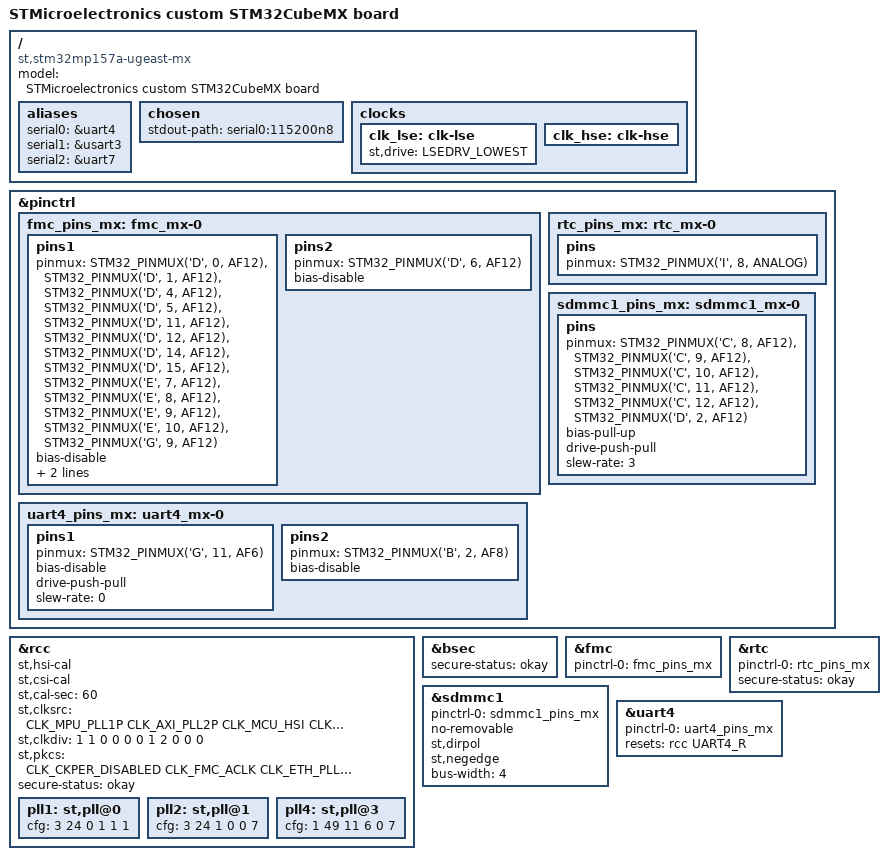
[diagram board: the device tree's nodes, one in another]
/* SPDX-License-Identifier: (GPL-2.0+ OR BSD-3-Clause) */
/*
 * Copyright (C) STMicroelectronics 2019 - All Rights Reserved
 * Author: STM32CubeMX code generation for STMicroelectronics.
 */

/dts-v1/;
#include <dt-bindings/clock/stm32mp1-clksrc.h>
#include "stm32mp15-mx.h"

#include "stm32mp157c.dtsi"
#include "stm32mp157cac-pinctrl.dtsi"
#include "stm32mp15-ddr.dtsi"
#include "stm32mp157c-security.dtsi"

/* USER CODE BEGIN includes */
/* USER CODE END includes */

/ {
	model = "STMicroelectronics custom STM32CubeMX board";
	compatible = "st,stm32mp157a-ugeast-mx", "st,stm32mp157";

	/* USER CODE BEGIN root */

	aliases {
		serial0 = &uart4;
		serial1 = &usart3;
		serial2 = &uart7;
	};

	chosen {
		stdout-path = "serial0:115200n8";
	};

	/* USER CODE END root */

clocks {
    /* USER CODE BEGIN clocks */
    /* USER CODE END clocks */

    clk_lse: clk-lse {
        /* USER CODE BEGIN clocks */
        /* USER CODE END clocks */
        st,drive=<LSEDRV_LOWEST>;
    };
    clk_hse: clk-hse {
        /* USER CODE BEGIN clocks */
        /* USER CODE END clocks */
    };
};

}; /*root*/

&pinctrl {
    fmc_pins_mx: fmc_mx-0 {
        pins1 {
            pinmux = <STM32_PINMUX('D', 0, AF12)>, /* FMC_D2 */
                     <STM32_PINMUX('D', 1, AF12)>, /* FMC_D3 */
                     <STM32_PINMUX('D', 4, AF12)>, /* FMC_NOE */
                     <STM32_PINMUX('D', 5, AF12)>, /* FMC_NWE */
                     <STM32_PINMUX('D', 11, AF12)>, /* FMC_CLE */
                     <STM32_PINMUX('D', 12, AF12)>, /* FMC_ALE */
                     <STM32_PINMUX('D', 14, AF12)>, /* FMC_D0 */
                     <STM32_PINMUX('D', 15, AF12)>, /* FMC_D1 */
                     <STM32_PINMUX('E', 7, AF12)>, /* FMC_D4 */
                     <STM32_PINMUX('E', 8, AF12)>, /* FMC_D5 */
                     <STM32_PINMUX('E', 9, AF12)>, /* FMC_D6 */
                     <STM32_PINMUX('E', 10, AF12)>, /* FMC_D7 */
                     <STM32_PINMUX('G', 9, AF12)>; /* FMC_NCE */
            bias-disable;
            drive-push-pull;
            slew-rate = <1>;
        };
        pins2 {
            pinmux = <STM32_PINMUX('D', 6, AF12)>; /* FMC_NWAIT */
            bias-disable;
        };
    };
    rtc_pins_mx: rtc_mx-0 {
        pins {
            pinmux = <STM32_PINMUX('I', 8, ANALOG)>; /* RTC_LSCO */
        };
    };
    sdmmc1_pins_mx: sdmmc1_mx-0 {
        pins {
            pinmux = <STM32_PINMUX('C', 8, AF12)>, /* SDMMC1_D0 */
                     <STM32_PINMUX('C', 9, AF12)>, /* SDMMC1_D1 */
                     <STM32_PINMUX('C', 10, AF12)>, /* SDMMC1_D2 */
                     <STM32_PINMUX('C', 11, AF12)>, /* SDMMC1_D3 */
                     <STM32_PINMUX('C', 12, AF12)>, /* SDMMC1_CK */
                     <STM32_PINMUX('D', 2, AF12)>; /* SDMMC1_CMD */
            bias-pull-up;
            drive-push-pull;
            slew-rate = <3>;
        };
    };
    uart4_pins_mx: uart4_mx-0 {
        pins1 {
            pinmux = <STM32_PINMUX('G', 11, AF6)>; /* UART4_TX */
            bias-disable;
            drive-push-pull;
            slew-rate = <0>;
        };
        pins2 {
            pinmux = <STM32_PINMUX('B', 2, AF8)>; /* UART4_RX */
            bias-disable;
        };
    };
};

&rcc {
    st,hsi-cal;
    st,csi-cal;
    st,cal-sec = <60>;
    st,clksrc = <
        CLK_MPU_PLL1P
        CLK_AXI_PLL2P
        CLK_MCU_HSI
        CLK_PLL12_HSI
        CLK_PLL3_HSE
        CLK_PLL4_HSE
        CLK_RTC_LSE
        CLK_MCO1_DISABLED
        CLK_MCO2_DISABLED
    >;
    st,clkdiv = <
        1         /*MPU*/
        1         /*AXI*/
        0         /*MCU*/
        0         /*APB1*/
        0         /*APB2*/
        0         /*APB3*/
        1         /*APB4*/
        2         /*APB5*/
        0         /*RTC*/
        0         /*MCO1*/
        0         /*MCO2*/
    >;
    st,pkcs = <
        CLK_CKPER_DISABLED
        CLK_FMC_ACLK
        CLK_ETH_PLL4P
        CLK_SDMMC12_HSI
        CLK_STGEN_HSI
        CLK_USBPHY_HSE
        CLK_SPI2S1_DISABLED
        CLK_SPI2S23_DISABLED
        CLK_SPI45_DISABLED
        CLK_SPI6_DISABLED
        CLK_I2C46_CSI
        CLK_SDMMC3_HCLK2
        CLK_USBO_PLL4R
        CLK_ADC_DISABLED
        CLK_CEC_DISABLED
        CLK_I2C12_PCLK1
        CLK_I2C35_DISABLED
        CLK_UART1_DISABLED
        CLK_UART24_PCLK1
        CLK_UART35_DISABLED
        CLK_UART6_DISABLED
        CLK_UART78_DISABLED
        CLK_SPDIF_PLL4P
        CLK_FDCAN_HSE
        CLK_SAI1_DISABLED
        CLK_SAI2_SPDIF
        CLK_SAI3_DISABLED
        CLK_SAI4_DISABLED
        CLK_LPTIM1_DISABLED
        CLK_LPTIM23_DISABLED
        CLK_LPTIM45_DISABLED
    >;
    pll1:st,pll@0 {
        cfg = < 3 24 0 1 1 1>;
    };
    pll2:st,pll@1 {
        cfg = < 3 24 1 0 0 7>;
    };
    pll4:st,pll@3 {
        cfg = < 1 49 11 6 0 7>;
    };
};

&bsec{
    status = "okay";
    secure-status = "okay";

    /* USER CODE BEGIN bsec */
    /* USER CODE END bsec */
};

&fmc{
    pinctrl-names = "default";
    pinctrl-0 = <&fmc_pins_mx>;
    status = "okay";

    /* USER CODE BEGIN fmc */
    /* USER CODE END fmc */
};

&rcc{
    status = "okay";
    secure-status = "okay";

    /* USER CODE BEGIN rcc */
    /* USER CODE END rcc */
};

&rtc{
    pinctrl-names = "default";
    pinctrl-0 = <&rtc_pins_mx>;
    status = "okay";
    secure-status = "okay";

    /* USER CODE BEGIN rtc */
    /* USER CODE END rtc */
};

&sdmmc1{
    pinctrl-names = "default";
    pinctrl-0 = <&sdmmc1_pins_mx>;
    status = "okay";

    /* USER CODE BEGIN sdmmc1 */
    no-removable;
    st,dirpol;
    st,negedge;
    bus-width=<4>;
    /* USER CODE END sdmmc1 */
};

&uart4{
    pinctrl-names = "default";
    pinctrl-0 = <&uart4_pins_mx>;
    status = "okay";

    /* USER CODE BEGIN uart4 */
    resets = <&rcc UART4_R>;
    /* USER CODE END uart4 */
};

/* USER CODE BEGIN addons */
/* USER CODE END addons */

